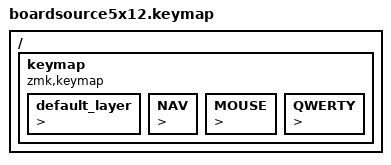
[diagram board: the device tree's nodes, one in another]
/*
 * Copyright (c) 2021 The ZMK Contributors
 *
 * SPDX-License-Identifier: MIT
 */
 
#include <behaviors.dtsi>
#include <dt-bindings/zmk/keys.h>
#include <dt-bindings/zmk/bt.h>
#include <dt-bindings/zmk/mouse.h>
#include <dt-bindings/zmk/outputs.h>

#define DEFAULT 0
#define NAV     1
#define MOUSE   2
#define QWERTY  3


/ {
    keymap {
        compatible = "zmk,keymap";

        default_layer {
//╭──────────┬──────────┬──────────┬──────────┬──────────┬──────────┬──────────┬──────────┬──────────┬──────────┬──────────┬──────────┬──────────┬──────────┬──────────────╮
    &kp ESC   &kp EQUAL    &kp N1     &kp N2     &kp N3     &kp N4     &kp N5     &kp N6     &kp N7     &kp N8     &kp N9     &kp N0    &kp SEMI  &kp PSCRN   &kp K_VOL_UP
//╰──────────┴──────────┴──────────┴──────────┴──────────┴──────────┴──────────┴──────────┴──────────┴──────────┴──────────┴──────────┴──────────┴──────────┴──────────────╯
//╭───────────────┬──────────┬──────────┬──────────┬──────────┬──────────┬──────────┬──────────┬──────────┬──────────┬──────────┬──────────┬────────────────┬──────────────╮
    &kp TAB         &kp SQT   &kp COMMA   &kp DOT     &kp P      &kp Y     &kp FSLH    & kp F     &kp G      &kp  C     &kp R      &kp L       &kp MINUS      &kp C_VOL_DN
//╰───────────────┴──────────┴──────────┴──────────┴──────────┴──────────┴──────────┴──────────┴──────────┴──────────┴──────────┴──────────┴────────────────┴──────────────╯
//╭─────────────┬──────────┬──────────┬──────────┬──────────┬──────────┬────────────────┬──────────┬──────────┬──────────┬──────────┬──────────┬──────────┬────────────────╮
    &kp BSPC       &kp A      &kp O       &kp E     &kp U      &kp I       &kp BSLH         &kp D     &kp H      &kp T      &kp N      &kp S    &kp RSHIFT    &kp ENTER
//╰─────────────┴──────────┴──────────┴──────────┴──────────┴──────────┴────────────────┴──────────┴──────────┴──────────┴──────────┴──────────┴──────────┴────────────────╯
//╭──────────┬──────────┬──────────┬──────────┬──────────┬──────────┬──────────┬──────────┬──────────┬──────────┬──────────┬──────────┬──────────┬──────────┬──────────────╮
    &tog MOUSE &kp LSHIFT   &kp Q      &kp J     &kp K       &kp X     &kp LBKT   &kp RBKT   &kp B       &kp M     &kp W      &kp V      &kp Z      &kp UP     &kp BT_NXT
//╰──────────┴──────────┴──────────┴──────────┴──────────┴──────────┴──────────┴──────────┴──────────┴──────────┴──────────┴──────────┴──────────┴──────────┴──────────────╯
//╭─────────────┬─────────┬─────────────┬───────────────────────────────┬──────────────┬─────────────────────┬──────────┬─────────────┬──────────┬──────────┬──────────────╮
    &kp LCTRL    &kp LGUI    &kp LALT              &kp SPACE                &mo MOUSE          &mo  NAV               &kp DEL    &kp RCTRL    &kp LEFT   &kp DOWN   &kp RIGHT
//╰─────────────┴─────────┴─────────────┴───────────────────────────────┴──────────────┴─────────────────────┴──────────┴─────────────┴──────────┴──────────┴──────────────╯
            >;
        };

        NAV {
//╭──────────┬──────────┬──────────┬──────────┬──────────┬──────────┬──────────┬──────────┬──────────┬──────────┬──────────┬──────────┬──────────┬──────────┬──────────────╮
    &trans       &trans    &kp F1     &kp F2     &kp F3     &kp F4     &kp F5     &kp F6     &kp F7     &kp F8     &kp F9     &kp F10    &kp F11  &kp F12      &trans
//╰──────────┴──────────┴──────────┴──────────┴──────────┴──────────┴──────────┴──────────┴──────────┴──────────┴──────────┴──────────┴──────────┴──────────┴──────────────╯
//╭───────────────┬──────────┬──────────┬──────────┬──────────┬──────────┬──────────┬──────────┬──────────┬──────────┬──────────┬──────────┬────────────────┬──────────────╮
    &trans          &trans     &trans     &kp UP     &kp K_APP   &kp ESC    &trans    &trans     &kp N7      &kp N8    &kp N9      &trans       &trans         &trans
//╰───────────────┴──────────┴──────────┴──────────┴──────────┴──────────┴──────────┴──────────┴──────────┴──────────┴──────────┴──────────┴────────────────┴──────────────╯
//╭─────────────┬──────────┬──────────┬──────────┬──────────┬──────────┬────────────────┬──────────┬──────────┬──────────┬──────────┬──────────┬──────────┬────────────────╮
    &trans       &kp LEFT    &kp LEFT   &kp DOWN   &kp RIGHT  &kp ENTER       &trans        &trans     &kp N4     &kp N5      &kp N6    &trans   &trans        &trans
//╰─────────────┴──────────┴──────────┴──────────┴──────────┴──────────┴────────────────┴──────────┴──────────┴──────────┴──────────┴──────────┴──────────┴────────────────╯
//╭──────────┬──────────┬──────────┬──────────┬──────────┬──────────┬──────────┬──────────┬──────────┬──────────┬──────────┬──────────┬──────────┬──────────┬──────────────╮
    &none      &trans      &trans      &trans      &trans     &trans   &trans     &trans     &kp N0      &kp N1     &kp N2      &kp N3      &trans      &trans     &trans
//╰──────────┴──────────┴──────────┴──────────┴──────────┴──────────┴──────────┴──────────┴──────────┴──────────┴──────────┴──────────┴──────────┴──────────┴──────────────╯
//╭─────────────┬─────────┬─────────────┬───────────────────────────────┬──────────────┬─────────────────────┬──────────┬─────────────┬──────────┬──────────┬──────────────╮
    &trans        &trans      &trans        &trans                          &trans          &trans              &trans      &trans      &trans       &trans     &trans 
//╰─────────────┴─────────┴─────────────┴───────────────────────────────┴──────────────┴─────────────────────┴──────────┴─────────────┴──────────┴──────────┴──────────────╯
        
            >;
        };

        MOUSE {
        
            >;
        };
        
        QWERTY{
        
            >;
        };

      
    };
};
